# CY8C5888LTI_LP097 register map
File version: 0.1
CY8C58LP
Registers are 8-bit, read-write, no defined reset value unless marked. A register's access mark holds for its fields unless they carry their own. Offsets are from the block's base; lines under a group give offsets from that group; [hi:lo] are bit positions; {n}, {i} and the like mark numbered series; 'fields as' and 'values as' point back to an identical list; <NAME> marks a mode.

## Memory map
0x00000000 Buttons_Status
0x00000000 JOYSTICK_ADC_XY_SAR — SAR ADC
0x00000000 RGB_PWM_blue
0x00000000 RGB_PWM_green
0x00000000 SEVEN_reg
0x00000000 UART_LOG — UART
0x00000000 RGB_PWM_red

## Buttons_Status
Base 0x00000000
0x40006468 Buttons_Status_STATUS_REG
0x40006488 Buttons_Status_MASK_REG
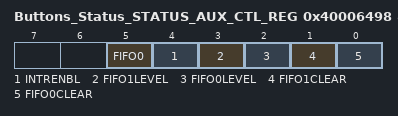
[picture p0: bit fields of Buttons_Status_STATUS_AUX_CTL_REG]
0x40006498 Buttons_Status_STATUS_AUX_CTL_REG
  [5] FIFO0 — FIFO0 clear
    1=ENABLED (Enable counter); 0=DISABLED (Disable counter)
  [4] INTRENBL — Enables or disables the Interrupt
    1=ENABLED (Interrupt enabled); 0=DISABLED (Interrupt disabled)
  [3] FIFO1LEVEL — FIFO level
    1=ENABLED (FIFO LVL: input mode: FIFO at least 1/2 empty; output mode: FIFO at least 1/2 full); 0=DISABLED (FIFO LVL: input mode: FIFO not full; output mode: FIFO not empty)
  [2] FIFO0LEVEL — FIFO level
    values as FIFO1LEVEL
  [1] FIFO1CLEAR — FIFO clear
    1=ENABLED (Clear FIFO state); 0=DISABLED (Normal FIFO operation)
  [0] FIFO0CLEAR — FIFO clear
    values as FIFO1CLEAR

## JOYSTICK_ADC_XY_SAR — SAR ADC
Base 0x00000000
0x40004616 SAR_TR0 — SAR trim register
{0x40005908+i} SAR_CSR{i} (i=0..6) — SAR status and control register {i}
0x40005B28 SAR_SW0 — SAR Analog Routing Register 0
{0x40005B28+i} SAR_SW{i} (i=2..4) — SAR Analog Routing Register {i}
0x40005B2E SAR_SW6 — SAR Analog Routing Register 6
0x40005B2F SAR_CLK — SAR Clock Selection Register
0x40005BA2 SAR_WRK 16-bit — SAR working register

## RGB_PWM_blue
Base 0x00000000
0x4000642E RGB_PWM_blue_COMPARE_Reg_ — UDB.D0 - Assigned Compare Value
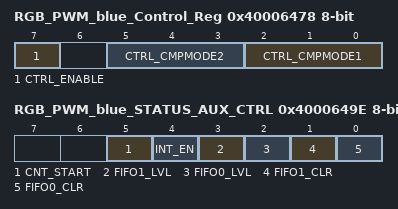
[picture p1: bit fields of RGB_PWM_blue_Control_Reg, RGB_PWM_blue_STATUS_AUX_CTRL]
0x40006478 RGB_PWM_blue_Control_Reg — UDB Control Register - Assigned Control Register Value
  [7] CTRL_ENABLE — Enable the PWM
  [5:3] CTRL_CMPMODE2 — Compare mode 2
  [2:0] CTRL_CMPMODE1 — Compare mode 1
0x4000649E RGB_PWM_blue_STATUS_AUX_CTRL — UDB Auxilliary Control Register
  [5] CNT_START — FIFO0 clear
    0=E_CNT_START0 (Disable counter); 1=E_CNT_START1 (Enable counter)
  [4] INT_EN
    0=E_INT_EN0 (Interrupt disabled); 1=E_INT_EN1 (Interrupt enabled)
  [3] FIFO1_LVL — FIFO level
    0=E_FIFO_LVL_0 (FIFO LVL: input mode: FIFO not full; output mode: FIFO not empty); 1=E_FIFO_LVL_1 (FIFO LVL: input mode: FIFO at least 1/2 empty; output mode: FIFO at least 1/2 full)
  [2] FIFO0_LVL — FIFO level
    values as FIFO1_LVL
  [1] FIFO1_CLR — FIFO1 clear
    0=E_FIFO_CLR_0 (Normal FIFO operation); 1=E_FIFO_CLR_1 (Clear FIFO state)
  [0] FIFO0_CLR — FIFO0 clear
    values as FIFO1_CLR

## RGB_PWM_green
Base 0x00000000
0x4000642D RGB_PWM_green_COMPARE_Reg_ — UDB.D0 - Assigned Compare Value
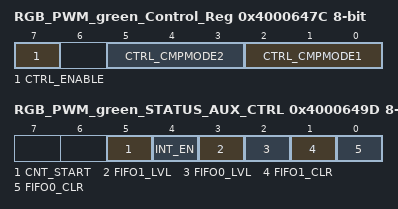
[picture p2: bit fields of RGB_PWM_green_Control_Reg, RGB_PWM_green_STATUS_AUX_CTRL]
0x4000647C RGB_PWM_green_Control_Reg — UDB Control Register - Assigned Control Register Value
  [7] CTRL_ENABLE — Enable the PWM
  [5:3] CTRL_CMPMODE2 — Compare mode 2
  [2:0] CTRL_CMPMODE1 — Compare mode 1
0x4000649D RGB_PWM_green_STATUS_AUX_CTRL — UDB Auxilliary Control Register
  fields as RGB_PWM_blue.RGB_PWM_blue_STATUS_AUX_CTRL

## SEVEN_reg
Base 0x00000000
0x40006579 SEVEN_reg_CONTROL_REG

## UART_LOG — UART
Base 0x00000000
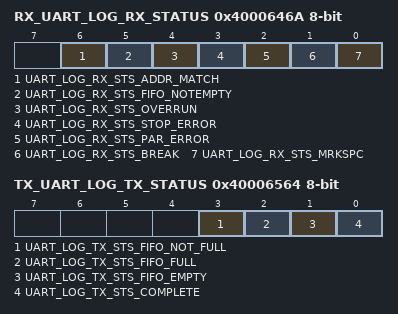
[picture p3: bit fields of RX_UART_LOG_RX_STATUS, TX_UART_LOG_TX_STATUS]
0x4000646A RX_UART_LOG_RX_STATUS — RX status register
  [6] UART_LOG_RX_STS_ADDR_MATCH ro, [5] UART_LOG_RX_STS_FIFO_NOTEMPTY ro, [4] UART_LOG_RX_STS_OVERRUN ro, [3] UART_LOG_RX_STS_STOP_ERROR ro, [2] UART_LOG_RX_STS_PAR_ERROR ro, [1] UART_LOG_RX_STS_BREAK ro, [0] UART_LOG_RX_STS_MRKSPC ro
0x40006529 RX_UART_LOG_RX_ADDRESS1 — RX Address1 Register
0x40006539 RX_UART_LOG_RX_ADDRESS2 — RX Address2 Register
0x40006544 TX_UART_LOG_TX_DATA — TX Data Register
0x40006549 RX_UART_LOG_RX_DATA — RX Data Register
0x40006564 TX_UART_LOG_TX_STATUS — TX status register
  [3] UART_LOG_TX_STS_FIFO_NOT_FULL ro, [2] UART_LOG_TX_STS_FIFO_FULL ro, [1] UART_LOG_TX_STS_FIFO_EMPTY ro, [0] UART_LOG_TX_STS_COMPLETE ro

## RGB_PWM_red
Base 0x00000000
0x4000642F RGB_PWM_red_COMPARE_Reg_ — UDB.D0 - Assigned Compare Value
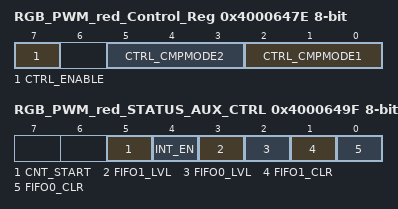
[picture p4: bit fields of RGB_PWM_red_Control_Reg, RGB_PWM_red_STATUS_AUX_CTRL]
0x4000647E RGB_PWM_red_Control_Reg — UDB Control Register - Assigned Control Register Value
  [7] CTRL_ENABLE — Enable the PWM
  [5:3] CTRL_CMPMODE2 — Compare mode 2
  [2:0] CTRL_CMPMODE1 — Compare mode 1
0x4000649F RGB_PWM_red_STATUS_AUX_CTRL — UDB Auxilliary Control Register
  fields as RGB_PWM_blue.RGB_PWM_blue_STATUS_AUX_CTRL
